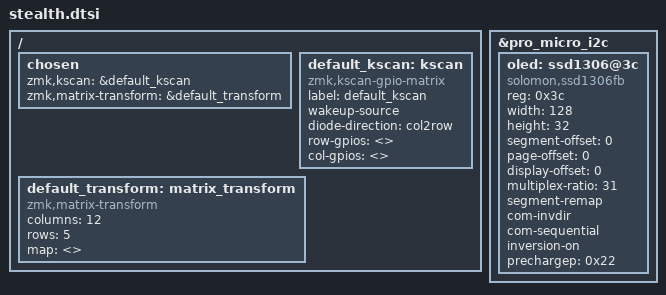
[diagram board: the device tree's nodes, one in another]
/*
 * Copyright (c) 2020 Pete Johanson
 *
 * SPDX-License-Identifier: MIT
 */

#include <dt-bindings/zmk/matrix_transform.h>


/ {
    chosen {
        zmk,kscan = &default_kscan;
        zmk,matrix-transform = &default_transform;
    };

    default_kscan: kscan {
        compatible = "zmk,kscan-gpio-matrix";
        label = "default_kscan";
        wakeup-source;
        diode-direction = "col2row";

        row-gpios = <>;

        col-gpios = <>;
    };

    default_transform: matrix_transform {
        compatible = "zmk,matrix-transform";
        columns = <12>;
        rows = <5>;
// | SW1  | SW2  | SW3  | SW4  | SW5  | SW6  |   | SW6  | SW5  | SW4  | SW3  | SW2  | SW1  |
// | SW7  | SW8  | SW9  | SW10 | SW11 | SW12 |   | SW12 | SW11 | SW10 | SW9  | SW8  | SW7  |
// | SW13 | SW14 | SW15 | SW16 | SW17 | SW18 |   | SW18 | SW17 | SW16 | SW15 | SW14 | SW13 |
// | SW19 | SW20 | SW21 | SW22 | SW23 | SW24 |   | SW24 | SW23 | SW22 | SW21 | SW20 | SW19 |
//                      | SW25 | SW26 | SW27 |   | SW27 | SW26 | SW25 |
        map = <>;
    };
};

&pro_micro_i2c {
    status = "okay";

    oled: ssd1306@3c {
        compatible = "solomon,ssd1306fb";
        reg = <0x3c>;
        width = <128>;
        height = <32>;
        segment-offset = <0>;
        page-offset = <0>;
        display-offset = <0>;
        multiplex-ratio = <31>;
        segment-remap;
        com-invdir;
        com-sequential;
        inversion-on;
        prechargep = <0x22>;
    };
};
